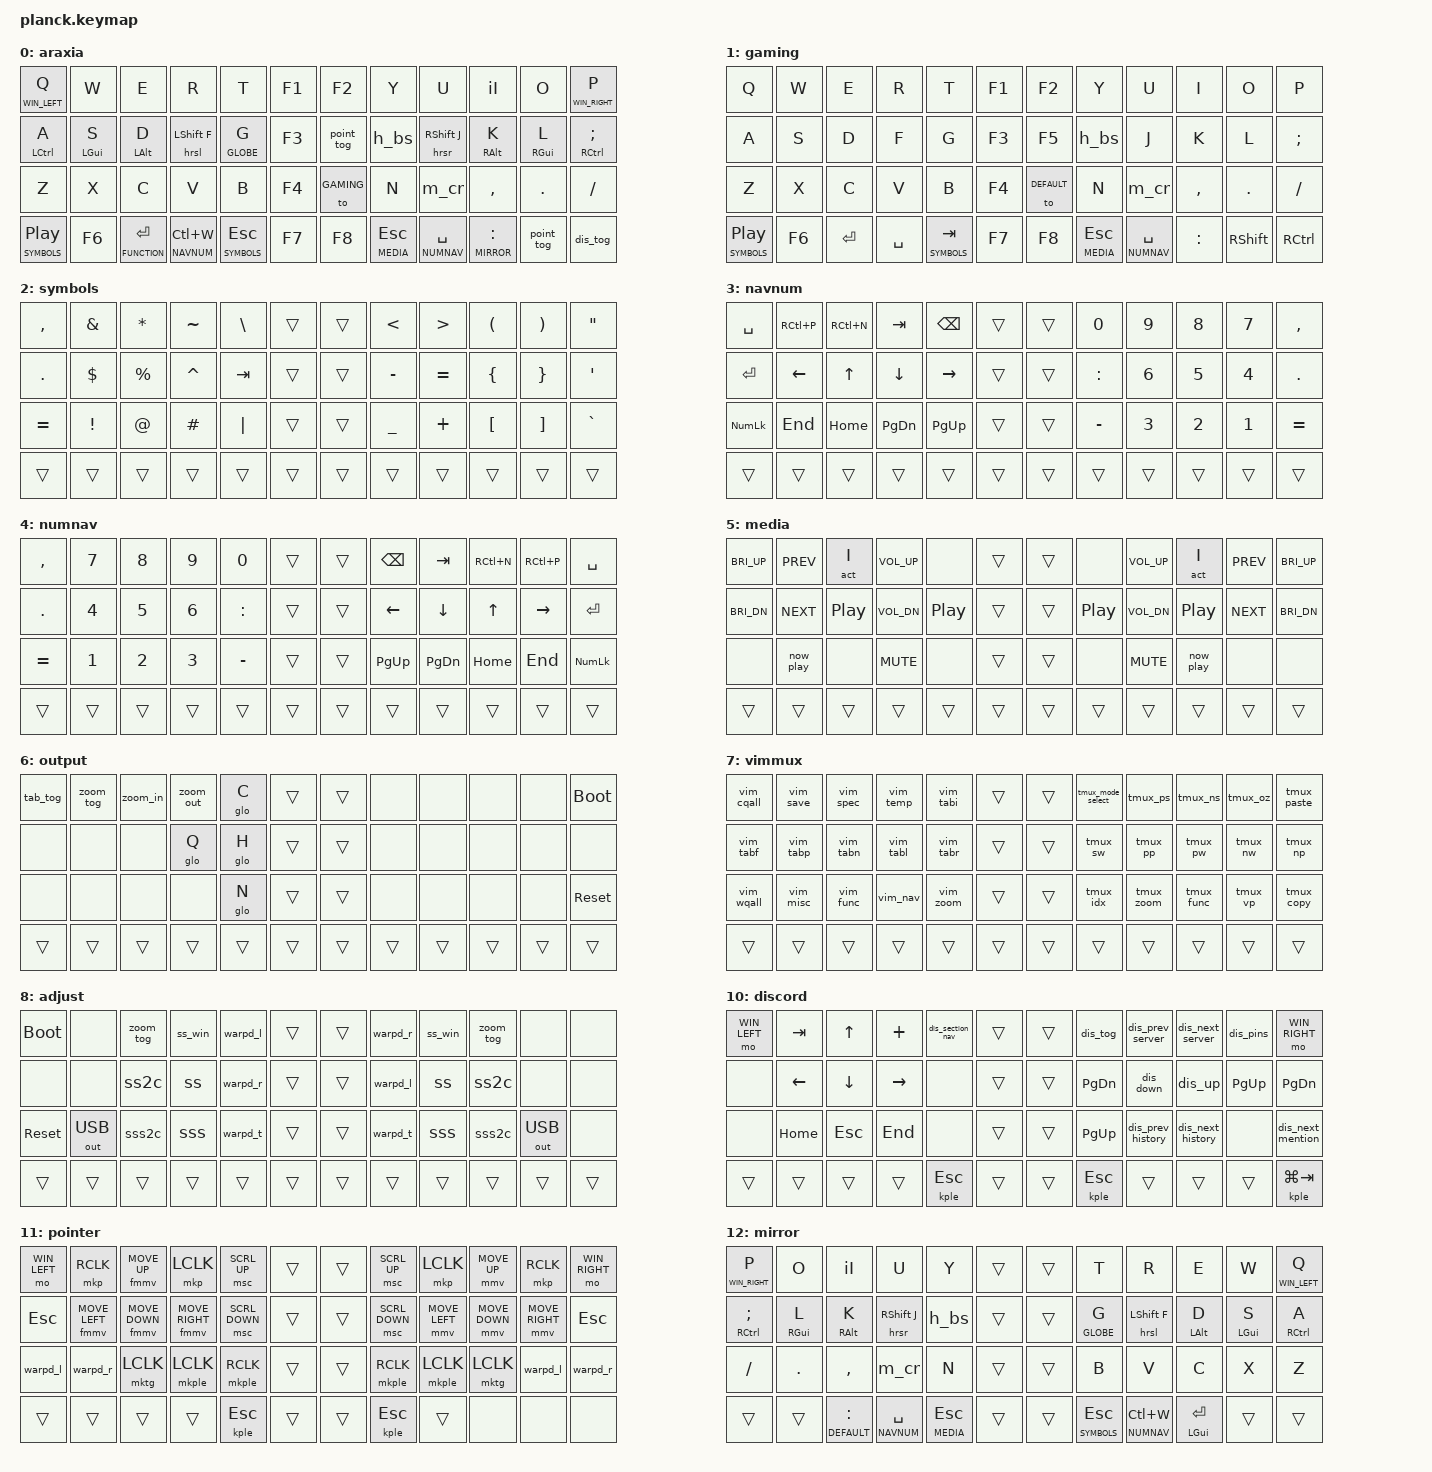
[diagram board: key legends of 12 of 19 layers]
// HEADERS {{{
#include <behaviors.dtsi>
#include <dt-bindings/zmk/keys.h>
#include <dt-bindings/zmk/outputs.h>
#include <dt-bindings/zmk/bt.h>
#include <dt-bindings/zmk/mouse.h>
#include <dt-bindings/zmk/rgb.h>
#include <dt-bindings/zmk/ext_power.h>

#include <behaviors/mouse_key_toggle.dtsi>

#include "shared.dtsi"
#include "planck_overrides.dtsi"

// }}}
/ {
// KEYMAP {{{
// n.b. display-name strings are truncated after 8 characters
    keymap {
        compatible = "zmk,keymap";

        /* 0 Layer */
        default {
            display-name = "araxia";
            bindings = <
&lttp WIN_LEFT Q    &kp W         &kp E                  &kp R               &kp T                &kp F1  &kp F2      &kp Y            &kp U               &iI                 &kp O         &lttp WIN_RIGHT P
&hrml LCTRL A       &hrml LGUI S  &hrml LALT D           &hrsl LSHIFT F      &hrml GLOBE G        &kp F3  &point_tog  &h_bs            &hrsr RSHIFT J      &hrmr RALT K        &hrmr RGUI L  &hrmr RCTRL SEMI
&kp Z               &kp X         &kp C                  &kp V               &kp B                &kp F4  &to GAMING  &kp N            &m_cr               &kp COMMA           &kp DOT       &kp SLASH
&lttp SYMBOLS C_PP  &kp F6        &lthp FUNCTION RETURN  &lthp NAVNUM LC(W)  &lthp SYMBOLS ESC    &kp F7  &kp F8      &lthp MEDIA ESC  &lttp NUMNAV SPACE  &mttp MIRROR COLON  &point_tog    &dis_tog
            >;
            sensor-bindings = <&inc_dec_kp C_VOL_UP C_VOL_DN>;
        };

        /* 1 Layer */
        gaming {
            display-name = "gaming";
            bindings = <
&kp Q               &kp W   &kp E       &kp R      &kp T                &kp F1  &kp F2         &kp Y            &kp U               &kp I      &kp O    &kp P
&kp A               &kp S   &kp D       &kp F      &kp G                &kp F3  &kp F5         &h_bs            &kp J               &kp K      &kp L    &kp SEMI
&kp Z               &kp X   &kp C       &kp V      &kp B                &kp F4  &to DEFAULT    &kp N            &m_cr               &kp COMMA  &kp DOT  &kp SLASH
&lttp SYMBOLS C_PP  &kp F6  &kp RETURN  &kp SPACE  &lthp SYMBOLS TAB    &kp F7  &kp F8         &lthp MEDIA ESC  &lttp NUMNAV SPACE  &kp COLON  &kp RSHIFT  &kp RCTRL
            >;
            sensor-bindings = <&inc_dec_kp C_VOL_UP C_VOL_DN>;
        };

        /* 2 Layer */
        symbols {
            display-name = "symbols";
            bindings = <
&kp COMMA  &kp AMPERSAND    &kp ASTERISK  &kp TILDE   &kp BACKSLASH     &trans  &trans    &kp LESS_THAN   &kp GREATER_THAN  &kp LEFT_PARENTHESIS  &kp RIGHT_PARENTHESIS  &kp DOUBLE_QUOTES
&kp DOT    &kp DOLLAR       &kp PERCENT   &kp CARET   &kp TAB           &trans  &trans    &kp MINUS       &kp EQUAL         &kp LEFT_BRACE        &kp RIGHT_BRACE        &kp SINGLE_QUOTE
&kp EQUAL  &kp EXCLAMATION  &kp AT        &kp POUND   &kp PIPE          &trans  &trans    &kp UNDERSCORE  &kp PLUS          &kp LEFT_BRACKET      &kp RIGHT_BRACKET      &kp GRAVE
&trans     &trans           &trans        &trans      &trans            &trans  &trans    &trans          &trans            &trans                &trans                 &trans
            >;
            sensor-bindings = <&inc_dec_kp LC(F) LC(B)>;
        };

        /* 3 Layer */
        navnum {
            display-name = "navnum";
            bindings = <
&kp SPACE       &kp RC(P)  &kp RC(N)  &kp TAB        &kp BACKSPACE     &trans  &trans    &kp N0     &kp N9  &kp N8  &kp N7  &kp COMMA
&kp RETURN      &kp LEFT   &kp UP     &kp DOWN       &kp RIGHT         &trans  &trans    &kp COLON  &kp N6  &kp N5  &kp N4  &kp DOT
&kp KP_NUMLOCK  &kp END    &kp HOME   &kp PAGE_DOWN  &kp PAGE_UP       &trans  &trans    &kp MINUS  &kp N3  &kp N2  &kp N1  &kp EQUAL
&trans          &trans     &trans     &trans         &trans            &trans  &trans    &trans     &trans  &trans  &trans  &trans
            >;
            sensor-bindings = <&inc_dec_kp LC(F) LC(B)>;
        };

        /* 4 Layer */
        numnav {
            display-name = "numnav";
            bindings = <
&kp COMMA  &kp N7  &kp N8  &kp N9  &kp N0        &trans  &trans    &kp BACKSPACE  &kp TAB        &kp RC(N)   &kp RC(P)   &kp SPACE
&kp DOT    &kp N4  &kp N5  &kp N6  &kp COLON     &trans  &trans    &kp LEFT       &kp DOWN       &kp UP      &kp RIGHT   &kp RETURN
&kp EQUAL  &kp N1  &kp N2  &kp N3  &kp MINUS     &trans  &trans    &kp PAGE_UP    &kp PAGE_DOWN  &kp HOME    &kp END     &kp KP_NUMLOCK
&trans     &trans  &trans  &trans  &trans        &trans  &trans    &trans         &trans         &trans      &trans      &trans
            >;
            sensor-bindings = <&inc_dec_kp PG_DN PG_UP>;
        };

        /* 5 Layer */
        media {
            display-name = "media";
            bindings = <
&kp C_BRI_UP  &kp C_PREV  &act I    &kp C_VOL_UP  &none        &trans  &trans    &none     &kp C_VOL_UP  &act I        &kp C_PREV    &kp C_BRI_UP
&kp C_BRI_DN  &kp C_NEXT  &kp C_PP  &kp C_VOL_DN  &kp C_PP     &trans  &trans    &kp C_PP  &kp C_VOL_DN  &kp C_PP      &kp C_NEXT    &kp C_BRI_DN
&none         &now_play   &none     &kp C_MUTE    &none        &trans  &trans    &none     &kp C_MUTE    &now_play     &none         &none
&trans        &trans      &trans    &trans        &trans       &trans  &trans    &trans    &trans        &trans        &trans        &trans
            >;
            sensor-bindings = <&inc_dec_kp C_BRI_UP C_BRI_DN>;
        };

        /* 6 Layer */
        /* No Bluetooth on Planck. */
        output {
            display-name = "output";
            bindings = <
&tab_tog  &zoom_tog  &zoom_in  &zoom_out  &glo C    &trans  &trans    &none   &none   &none   &none   &bootloader
&none     &none      &none     &glo Q     &glo H    &trans  &trans    &none   &none   &none   &none   &none
&none     &none      &none     &none      &glo N    &trans  &trans    &none   &none   &none   &none   &sys_reset
&trans    &trans     &trans    &trans     &trans    &trans  &trans    &trans  &trans  &trans  &trans  &trans
            >;
        };

        /* 7 Layer */
        vimmux {
            display-name = "vimmux";
            bindings = <
&vim_cqall  &vim_save  &vim_spec  &vim_temp  &vim_tabi    &trans  &trans    &tmux_mode_select  &tmux_ps    &tmux_ns    &tmux_oz  &tmux_paste
&vim_tabf   &vim_tabp  &vim_tabn  &vim_tabl  &vim_tabr    &trans  &trans    &tmux_sw           &tmux_pp    &tmux_pw    &tmux_nw  &tmux_np
&vim_wqall  &vim_misc  &vim_func  &vim_nav   &vim_zoom    &trans  &trans    &tmux_idx          &tmux_zoom  &tmux_func  &tmux_vp  &tmux_copy
&trans      &trans     &trans     &trans     &trans       &trans  &trans    &trans             &trans      &trans      &trans    &trans
            >;
        };

        /* 8 Layer */
        adjust {
            display-name = "adjust";
            bindings = <
&bootloader  &none         &zoom_tog &ss_win  &warpd_l    &trans  &trans    &warpd_r  &ss_win  &zoom_tog  &none         &none
&none        &none         &ss2c     &ss      &warpd_r    &trans  &trans    &warpd_l  &ss      &ss2c      &none         &none
&sys_reset   &out OUT_USB  &sss2c    &sss     &warpd_t    &trans  &trans    &warpd_t  &sss     &sss2c     &out OUT_USB  &none
&trans       &trans        &trans    &trans   &trans      &trans  &trans    &trans    &trans   &trans     &trans        &trans
            >;
        };

        /* 9 Layer */
        /* Do not use this then-layer for regular layer switching */
        lighting {
            display-name = "lighting";
            bindings = <
&trans  &none   &rgb_ug RGB_BRI  &rgb_ug RGB_BRD  &rgb_ug RGB_COLOR_HSB(25,100,0)     &trans  &trans    &ext_power EP_TOG  &glo N  &none   &none   &trans
&none   &none   &rgb_ug RGB_SAI  &rgb_ug RGB_SAD  &rgb_ug RGB_COLOR_HSB(25,100,80)    &trans  &trans    &none              &glo Q  &none   &none   &none
&none   &none   &rgb_ug RGB_HUI  &rgb_ug RGB_HUD  &rgb_ug RGB_COLOR_HSB(25,0,100)     &trans  &trans    &none              &none   &none   &none   &none
&trans  &trans  &trans           &trans           &trans                              &trans  &trans    &trans             &trans  &trans  &trans  &trans
            >;
        };

        /* 10 Layer */
        discord {
            display-name = "discord";
            bindings = <
&mo WIN_LEFT  &kp TAB   &kp UP    &kp PLUS   &dis_section_nav    &trans  &trans    &dis_tog       &dis_prev_server      &dis_next_server       &dis_pins    &mo WIN_RIGHT
&none         &kp LEFT  &kp DOWN  &kp RIGHT  &none               &trans  &trans    &kp PAGE_DOWN  &dis_down             &dis_up                &kp PAGE_UP  &kp PAGE_DOWN
&none         &kp HOME  &kp ESC   &kp END    &none               &trans  &trans    &kp PAGE_UP    &dis_prev_history     &dis_next_history      &none        &dis_next_mention
&trans        &trans    &trans    &trans     &kple ESC           &trans  &trans    &kple ESC      &trans                &trans                 &trans       &kple LG(TAB)
            >;
            sensor-bindings = <&rot_discord>;
        };

        /* 11 Layer */
        pointer {
            display-name = "pointer";
            bindings = <
&mo WIN_LEFT  &mkp RCLK        &fmmv MOVE_UP    &mkp LCLK         &msc SCRL_UP      &trans  &trans    &msc SCRL_UP    &mkp LCLK       &mmv MOVE_UP    &mkp RCLK        &mo WIN_RIGHT
&kp ESC       &fmmv MOVE_LEFT  &fmmv MOVE_DOWN  &fmmv MOVE_RIGHT  &msc SCRL_DOWN    &trans  &trans    &msc SCRL_DOWN  &mmv MOVE_LEFT  &mmv MOVE_DOWN  &mmv MOVE_RIGHT  &kp ESC
&warpd_l      &warpd_r         &mktg LCLK       &mkple LCLK       &mkple RCLK       &trans  &trans    &mkple RCLK     &mkple LCLK     &mktg LCLK      &warpd_l         &warpd_r
&trans        &trans           &trans           &trans            &kple ESC         &trans  &trans    &kple ESC       &trans          &none           &none            &none
            >;
            sensor-bindings = <&rot_msc MOVE_X(40) MOVE_X(-40)>;
        };

        /* 12 Layer */
        mirror {
            display-name = "mirror";
            bindings = <
&lttp WIN_RIGHT P  &kp O         &iI                  &kp U               &kp Y              &trans  &trans    &kp T              &kp R               &kp E              &kp W         &lttp WIN_LEFT Q
&hrmr RCTRL SEMI   &hrmr RGUI L  &hrmr RALT K         &hrsr RSHIFT J      &h_bs              &trans  &trans    &hrml GLOBE G      &hrsl LSHIFT F      &hrml LALT D       &hrml LGUI S  &hrml RCTRL A
&kp SLASH          &kp DOT       &kp COMMA            &m_cr               &kp N              &trans  &trans    &kp B              &kp V               &kp C              &kp X         &kp Z
&trans             &trans        &lthp DEFAULT COLON  &lthp NAVNUM SPACE  &lthp MEDIA ESC    &trans  &trans    &lthp SYMBOLS ESC  &lthp NUMNAV LC(W)  &mthp LGUI RETURN  &trans        &trans
            >;
        };

        /* 13 Layer */
        window_left {
            display-name = "move [L]";
            bindings = <
&trans       &forward   &backward   &tab_next   &tab_prev    &trans  &trans    &act Y  &act U  &act I          &act O             &act P
&kp C_SLEEP  &win_quad  &win_third  &win_half   &win_full    &trans  &trans    &act H  &act J  &act K          &act L             &act COLON
&kp C_POWER  &none      &none       &sk LSHIFT  &win_next    &trans  &trans    &act N  &act M  &act LESS_THAN  &act GREATER_THAN  &act QUESTION
&trans       &trans     &trans      &trans      &trans       &trans  &trans    &trans  &trans  &trans          &trans             &trans
            >;
        };

        /*  14 Layer */
        window_right {
            display-name = "move [R]";
            bindings = <
&act Q  &act W  &act E  &act R  &act T    &trans  &trans    &tab_prev  &tab_next   &backward   &forward   &trans
&act A  &act S  &act D  &act F  &act G    &trans  &trans    &win_full  &win_half   &win_third  &win_quad  &kp C_SLEEP
&act Z  &act X  &act C  &act V  &act B    &trans  &trans    &win_next  &sk RSHIFT  &none       &none      &kp C_POWER
&trans  &trans  &trans  &trans  &trans    &trans  &trans    &trans     &trans      &trans      &trans     &trans
            >;
        };


        /*  15 Layer */
        act {
            display-name = "act";
            bindings = <
&act Q  &act W  &act E  &act R  &act T     &trans  &trans    &act Y  &act U  &act I          &act O             &act P
&act A  &act S  &act D  &act F  &act G     &trans  &trans    &act H  &act J  &act K          &act L             &act COLON
&act Z  &act X  &act C  &act V  &act B     &trans  &trans    &act N  &act M  &act LESS_THAN  &act GREATER_THAN  &act QUESTION
&trans  &trans  &trans  &trans  &trans     &trans  &trans    &trans  &trans  &trans          &trans             &trans
            >;
        };

        /* 16 Layer */
        func {
            display-name = "func";
            bindings = <
&kp F1  &kp F2   &kp F3   &kp F4   &f2_menu      &trans  &trans    &help_menu  &kp F13   &kp F14   &kp F15    &kp F16
&kp F5  &kp F6   &kp F7   &kp F8   &f2_status    &trans  &trans    &point_tog  &kp F17   &kp F18   &kp F19    &kp F20
&kp F9  &kp F10  &kp F11  &kp F12  &f2_dock      &trans  &trans    &dis_tog    &kp F21   &kp F22   &kp F23    &kp F24
&trans  &trans   &trans   &trans   &trans        &trans  &trans    &trans      &trans    &trans    &trans     &trans
            >;
        };

        /* 17 Layer */
        free {
            display-name = "free";
            bindings = <
&none  &none  &none  &none  &none    &trans  &trans    &none  &none  &none  &none  &none
&none  &none  &none  &none  &none    &trans  &trans    &none  &none  &none  &none  &none
&none  &none  &none  &none  &none    &trans  &trans    &none  &none  &none  &none  &none
&none  &none  &none  &none  &none    &trans  &trans    &none  &none  &none  &none  &none
            >;
        };

        /* 18 Layer */
        outer {
            display-name = "outer";
            bindings = <
&none  &none  &none  &none  &none    &trans  &trans    &none  &none  &none  &none  &none
&none  &none  &none  &none  &none    &trans  &trans    &none  &none  &none  &none  &none
&none  &none  &none  &none  &none    &trans  &trans    &none  &none  &none  &none  &none
&none  &none  &none  &none  &none    &trans  &trans    &none  &none  &none  &none  &none
            >;
        };

    };

};
// }}}
/* vim: set ft=dts: */
